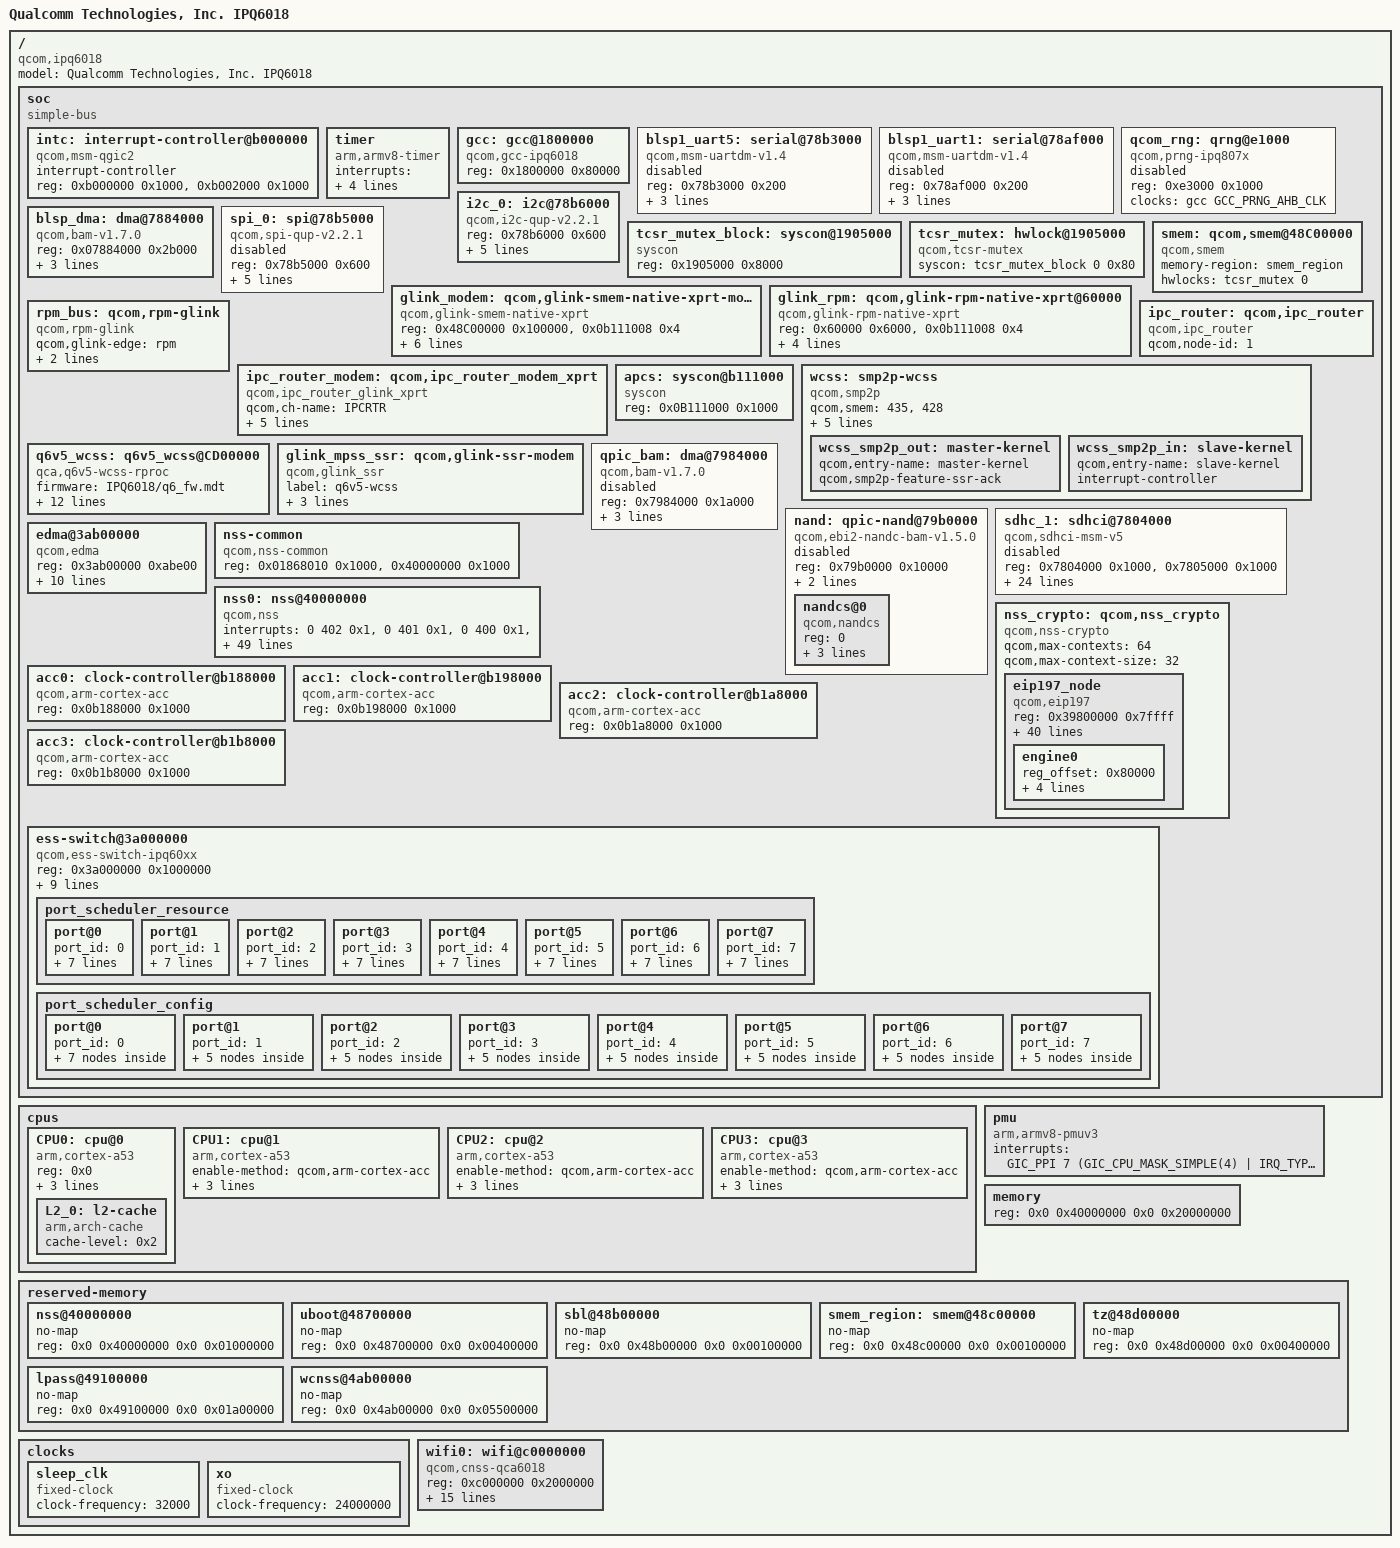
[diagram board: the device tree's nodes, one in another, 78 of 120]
/*
 * Copyright (c) 2018, The Linux Foundation. All rights reserved.
 *
 * Permission to use, copy, modify, and/or distribute this software for any
 * purpose with or without fee is hereby granted, provided that the above
 * copyright notice and this permission notice appear in all copies.
 *
 * THE SOFTWARE IS PROVIDED "AS IS" AND THE AUTHOR DISCLAIMS ALL WARRANTIES
 * WITH REGARD TO THIS SOFTWARE INCLUDING ALL IMPLIED WARRANTIES OF
 * MERCHANTABILITY AND FITNESS. IN NO EVENT SHALL THE AUTHOR BE LIABLE FOR
 * ANY SPECIAL, DIRECT, INDIRECT, OR CONSEQUENTIAL DAMAGES OR ANY DAMAGES
 * WHATSOEVER RESULTING FROM LOSS OF USE, DATA OR PROFITS, WHETHER IN AN
 * ACTION OF CONTRACT, NEGLIGENCE OR OTHER TORTIOUS ACTION, ARISING OUT OF
 * OR IN CONNECTION WITH THE USE OR PERFORMANCE OF THIS SOFTWARE.
 */

#include <dt-bindings/interrupt-controller/arm-gic.h>
#include <dt-bindings/clock/qcom,gcc-ipq6018.h>

/ {
	model = "Qualcomm Technologies, Inc. IPQ6018";
	compatible = "qcom,ipq6018";

	soc: soc {
		#address-cells = <0x1>;
		#size-cells = <0x1>;
		ranges = <0 0 0 0xffffffff>;
		compatible = "simple-bus";

		intc: interrupt-controller@b000000 {
			compatible = "qcom,msm-qgic2";
			interrupt-controller;
			#interrupt-cells = <0x3>;
			reg = <0xb000000 0x1000>, <0xb002000 0x1000>;
		};

		timer {
			compatible = "arm,armv8-timer";
			interrupts = <GIC_PPI 2 (GIC_CPU_MASK_SIMPLE(4) | IRQ_TYPE_LEVEL_LOW)>,
				     <GIC_PPI 3 (GIC_CPU_MASK_SIMPLE(4) | IRQ_TYPE_LEVEL_LOW)>,
				     <GIC_PPI 4 (GIC_CPU_MASK_SIMPLE(4) | IRQ_TYPE_LEVEL_LOW)>,
				     <GIC_PPI 1 (GIC_CPU_MASK_SIMPLE(4) | IRQ_TYPE_LEVEL_LOW)>;
		};

		gcc: gcc@1800000 {
			compatible = "qcom,gcc-ipq6018";
			reg = <0x1800000 0x80000>;
			#clock-cells = <0x1>;
			#reset-cells = <0x1>;
		};

		blsp1_uart5: serial@78b3000 {
			compatible = "qcom,msm-uartdm-v1.4", "qcom,msm-uartdm";
			reg = <0x78b3000 0x200>;
			interrupts = <GIC_SPI 308 IRQ_TYPE_LEVEL_HIGH>;
			clocks = <&gcc GCC_BLSP1_UART5_APPS_CLK>,
				 <&gcc GCC_BLSP1_AHB_CLK>;
			clock-names = "core", "iface";
			status = "disabled";
		};

		blsp1_uart1: serial@78af000 {
			compatible = "qcom,msm-uartdm-v1.4", "qcom,msm-uartdm";
			reg = <0x78af000 0x200>;
			interrupts = <GIC_SPI 107 IRQ_TYPE_LEVEL_HIGH>;
			clocks = <&gcc GCC_BLSP1_UART1_APPS_CLK>,
				 <&gcc GCC_BLSP1_AHB_CLK>;
			clock-names = "core", "iface";
			status = "disabled";
		};

		qcom_rng: qrng@e1000 {
			compatible = "qcom,prng-ipq807x";
			reg = <0xe3000 0x1000>;
			clocks = <&gcc GCC_PRNG_AHB_CLK>;
			clock-names = "core";
			status = "disabled";
		};

		blsp_dma: dma@7884000 {
			compatible = "qcom,bam-v1.7.0";
			reg = <0x07884000 0x2b000>;
			interrupts = <0 238 0>;
			clocks = <&gcc GCC_BLSP1_AHB_CLK>;
			clock-names = "bam_clk";
			#dma-cells = <1>;
			qcom,ee = <0>;
		};

		i2c_0: i2c@78b6000 {
			compatible = "qcom,i2c-qup-v2.2.1";
			#address-cells = <1>;
			#size-cells = <0>;
			reg = <0x78b6000 0x600>;
			interrupts = <GIC_SPI 96 0x4>;
			clocks = <&gcc GCC_BLSP1_AHB_CLK>,
				<&gcc GCC_BLSP1_QUP2_I2C_APPS_CLK>;
			clock-names = "iface", "core";
			clock-frequency  = <400000>;
			dmas = <&blsp_dma 15>, <&blsp_dma 14>;
			dma-names = "rx", "tx";
		};

		spi_0: spi@78b5000 { /* BLSP1 QUP0 */
			compatible = "qcom,spi-qup-v2.2.1";
			#address-cells = <1>;
			#size-cells = <0>;
			reg = <0x78b5000 0x600>;
			interrupts = <0 95 0>;
			spi-max-frequency = <50000000>;
			clocks = <&gcc GCC_BLSP1_QUP1_SPI_APPS_CLK>,
				<&gcc GCC_BLSP1_AHB_CLK>;
			clock-names = "core", "iface";
			dmas = <&blsp_dma 12>, <&blsp_dma 13>;
			dma-names = "tx", "rx";
			status = "disabled";
		};

		tcsr_mutex_block: syscon@1905000 {
			compatible = "syscon";
			reg = <0x1905000 0x8000>;
		};

		tcsr_mutex: hwlock@1905000 {
			compatible = "qcom,tcsr-mutex";
			syscon = <&tcsr_mutex_block 0 0x80>;
			#hwlock-cells = <1>;
		};

		smem: qcom,smem@48C00000 {
			compatible = "qcom,smem";
			memory-region = <&smem_region>;
			hwlocks = <&tcsr_mutex 0>;
		};

		glink_modem: qcom,glink-smem-native-xprt-modem@48C00000 {
			compatible = "qcom,glink-smem-native-xprt";
			reg = <0x48C00000 0x100000>, <0x0b111008 0x4>;
			reg-names = "smem", "irq-reg-base";
			qcom,irq-mask = <0x100>;
			interrupts = <0 321 1>;
			label = "mpss";
			qcom,subsys-id = <1>;
			smem-entry = <478>, <479>, <480>;
			smem-entry-names = "ch", "tx_fifo", "rx_fifo";
		};

		glink_rpm: qcom,glink-rpm-native-xprt@60000 {
			compatible = "qcom,glink-rpm-native-xprt";
			reg = <0x60000 0x6000>, <0x0b111008 0x4>;
			reg-names = "msgram", "irq-reg-base";
			qcom,irq-mask = <0x1>;
			interrupts = <GIC_SPI 168 IRQ_TYPE_EDGE_RISING>;
			label = "rpm";
			qcom,subsys-id = <6>;
			status = "ok";
		};

		rpm_bus: qcom,rpm-glink {
			compatible = "qcom,rpm-glink";
			qcom,glink-edge = "rpm";
			rpm-channel-name = "rpm_requests";
			qcom,rpm-channel-type = <15>; //SMD_APPS_RPM
			status = "ok";
		};

		ipc_router: qcom,ipc_router {
			compatible = "qcom,ipc_router";
			qcom,node-id = <1>;
		};

		ipc_router_modem: qcom,ipc_router_modem_xprt {
			compatible = "qcom,ipc_router_glink_xprt";
			qcom,ch-name = "IPCRTR";
			qcom,xprt-remote = "mpss";
			qcom,glink-xprt = "smem";
			qcom,xprt-linkid = <1>;
			qcom,xprt-version = <1>;
			qcom,fragmented-data;
		};

		apcs: syscon@b111000 {
			compatible = "syscon";
			reg = <0x0B111000 0x1000>;
		};

		wcss: smp2p-wcss {
			compatible = "qcom,smp2p";
			qcom,smem = <435>, <428>;

			interrupt-parent = <&intc>;
			interrupts = <0 322 1>;

			qcom,ipc = <&apcs 8 9>;

			qcom,local-pid = <0>;
			qcom,remote-pid = <1>;

			wcss_smp2p_out: master-kernel {
				qcom,entry-name = "master-kernel";
				qcom,smp2p-feature-ssr-ack;
				#qcom,smem-state-cells = <1>;
			};

			wcss_smp2p_in: slave-kernel {
				qcom,entry-name = "slave-kernel";

				interrupt-controller;
				#interrupt-cells = <2>;
			};
		};

		q6v5_wcss: q6v5_wcss@CD00000 {
			compatible = "qca,q6v5-wcss-rproc";
			firmware = "IPQ6018/q6_fw.mdt";
			reg = <0xCD00000 0x4040>,
				<0x194f000 0x10>,
				<0x1952000 0x10>,
				<0x4ab000 0x20>,
				<0x1818000 0x110>,
				<0x1859000 0x10>,
				<0x1945000 0x10>;
			reg-names = "wcss-base",
					"tcsr-q6-base",
					"tcsr-base",
					"mpm-base",
					"gcc-wcss-bcr-base",
					"gcc-wcss-misc-base",
					"tcsr-global";
			qca,auto-restart;
			qca,extended-intc;
			interrupts-extended = <&intc 0 325 1>,
				<&wcss_smp2p_in 0 0>,
				<&wcss_smp2p_in 1 0>,
				<&wcss_smp2p_in 3 0>;
			interrupt-names = "wdog",
				  "qcom,gpio-err-fatal",
				  "qcom,gpio-err-ready",
				  "qcom,gpio-stop-ack";
			qcom,smem-states = <&wcss_smp2p_out 0>,
				   <&wcss_smp2p_out 1>;
			qcom,smem-state-names = "shutdown",
					"stop";
		};

		glink_mpss_ssr: qcom,glink-ssr-modem {
			compatible = "qcom,glink_ssr";
			label = "q6v5-wcss";
			qcom,edge = "mpss";
			qca,no-notify-edges;
			qcom,xprt = "smem";
		};

		qpic_bam: dma@7984000{
			compatible = "qcom,bam-v1.7.0";
			reg = <0x7984000 0x1a000>;
			interrupts = <0 146 0>;
			clocks = <&gcc GCC_QPIC_AHB_CLK>;
			clock-names = "bam_clk";
			#dma-cells = <1>;
			qcom,ee = <0>;
			status = "disbaled";
		};

		nand: qpic-nand@79b0000 {
			compatible = "qcom,ebi2-nandc-bam-v1.5.0";
			reg = <0x79b0000 0x10000>;
			#address-cells = <1>;
			#size-cells = <0>;
			clocks = <&gcc GCC_QPIC_CLK>,
				<&gcc GCC_QPIC_AHB_CLK>;
			clock-names = "core", "aon";

			dmas = <&qpic_bam 0>,
				<&qpic_bam 1>,
				<&qpic_bam 2>;
			dma-names = "tx", "rx", "cmd";
			status = "disabled";

			nandcs@0 {
				compatible = "qcom,nandcs";
				reg = <0>;
				#address-cells = <1>;
				#size-cells = <1>;

				nand-ecc-strength = <4>;
				nand-ecc-step-size = <512>;
				nand-bus-width = <8>;
			};
		};

		sdhc_1: sdhci@7804000 {
			compatible = "qcom,sdhci-msm-v5";
			reg = <0x7804000 0x1000>, <0x7805000 0x1000>;
			reg-names = "hc_mem", "cmdq_mem";

			interrupts = <0 123 0>, <0 138 0>;
			interrupt-names = "hc_irq", "pwr_irq";

			qcom,bus-width = <8>;

			qcom,dedicated-io = <1>;

			/* device core power supply */
			qcom,vdd-voltage-level = <2900000 2900000>;
			qcom,vdd-current-level = <200 570000>;

			/* device communication power supply */
			qcom,vdd-io-lpm-sup;
			qcom,vdd-io-voltage-level = <1800000 1800000>;
			qcom,vdd-io-current-level = <200 325000>;
			qcom,vdd-io-always-on;

			qcom,cpu-dma-latency-us = <701>;
			qcom,msm-bus,name = "sdhc1";
			qcom,msm-bus,num-cases = <9>;
			qcom,msm-bus,num-paths = <1>;
			qcom,msm-bus,vectors-KBps = <78 512 0 0>, /* No vote */
				<78 512 1046 3200>,    /* 400 KB/s*/
				<78 512 52286 160000>, /* 20 MB/s */
				<78 512 65360 200000>, /* 25 MB/s */
				<78 512 130718 400000>, /* 50 MB/s */
				<78 512 261438 800000>, /* 100 MB/s */
				<78 512 261438 800000>, /* 200 MB/s */
				<78 512 261438 800000>, /* 400 MB/s */
				<78 512 1338562 4096000>; /* Max. bandwidth */
			qcom,bus-bw-vectors-bps = <0 400000 20000000 25000000 \
						50000000 100000000 200000000 \
						400000000 4294967295>;

			clocks = <&gcc GCC_SDCC1_AHB_CLK>,
				 <&gcc GCC_SDCC1_APPS_CLK>;
			clock-names = "iface_clk", "core_clk";
			qcom,large-address-bus;
			qcom,disable-aggressive-pm;

			status = "disabled";
		};

		edma@3ab00000 {
			compatible = "qcom,edma";
			reg = <0x3ab00000 0xabe00>;
			reg-names = "edma-reg-base";
			qcom,txdesc-ring-start = <23>;
			qcom,txdesc-rings = <1>;
			qcom,txcmpl-ring-start = <23>;
			qcom,txcmpl-rings = <1>;
			qcom,rxfill-ring-start = <7>;
			qcom,rxfill-rings = <1>;
			qcom,rxdesc-ring-start = <15>;
			qcom,rxdesc-rings = <1>;
			interrupts = <0 378 4>,
				   <0 354 4>,
				   <0 346 4>,
				   <0 379 4>;
			resets = <&gcc GCC_EDMA_HW_RESET>;
			reset-names = "edma_rst";
		};

		nss-common {
			compatible = "qcom,nss-common";
			reg = <0x01868010 0x1000>, <0x40000000 0x1000>;
			reg-names = "nss-misc-reset", "nss-misc-reset-flag";
		};

		nss0: nss@40000000 {
			compatible = "qcom,nss";
			interrupts = <0 402 0x1>, <0 401 0x1>, <0 400 0x1>,
				     <0 399 0x1>, <0 398 0x1>, <0 397 0x1>,
				     <0 396 0x1>, <0 395 0x1>, <0 394 0x1>;
			reg = <0x39000000 0x1000>, <0x0b111000 0x1000>;
			reg-names = "nphys", "qgic-phys";
			clocks = <&gcc GCC_NSS_NOC_CLK>,
				 <&gcc GCC_NSS_PTP_REF_CLK>,
				 <&gcc GCC_NSS_CSR_CLK>, <&gcc GCC_NSS_CFG_CLK>,
				 <&gcc GCC_NSSNOC_QOSGEN_REF_CLK>,
				 <&gcc GCC_MEM_NOC_NSS_AXI_CLK>,
				 <&gcc GCC_NSSNOC_SNOC_CLK>,
				 <&gcc GCC_NSSNOC_TIMEOUT_REF_CLK>,
				 <&gcc GCC_NSS_CE_AXI_CLK>,
				 <&gcc GCC_NSS_CE_APB_CLK>,
				 <&gcc GCC_NSSNOC_CE_AXI_CLK>,
				 <&gcc GCC_NSSNOC_CE_APB_CLK>,
				 <&gcc GCC_NSSNOC_UBI0_AHB_CLK>,
				 <&gcc GCC_UBI0_CORE_CLK>,
				 <&gcc GCC_UBI0_AHB_CLK>,
				 <&gcc GCC_UBI0_AXI_CLK>,
				 <&gcc GCC_UBI0_NC_AXI_CLK>;
			clock-names = "nss-noc-clk", "nss-ptp-ref-clk",
				      "nss-csr-clk", "nss-cfg-clk",
				      "nss-nssnoc-qosgen-ref-clk",
				      "nss-mem-noc-nss-axi-clk",
				      "nss-nssnoc-snoc-clk",
				      "nss-nssnoc-timeout-ref-clk",
				      "nss-ce-axi-clk", "nss-ce-apb-clk",
				      "nss-nssnoc-ce-axi-clk",
				      "nss-nssnoc-ce-apb-clk",
				      "nss-nssnoc-ahb-clk",
				      "nss-core-clk", "nss-ahb-clk",
				      "nss-axi-clk", "nss-nc-axi-clk";
			qcom,id = <0>;
			qcom,num-queue = <4>;
			qcom,num-irq = <9>;
			qcom,num-pri = <4>;
			qcom,load-addr = <0x40000000>;
			qcom,low-frequency = <748800000>;
			qcom,mid-frequency = <1497600000>;
			qcom,max-frequency = <1497600000>;
			qcom,bridge-enabled;
			qcom,ipv4-enabled;
			qcom,ipv4-reasm-enabled;
			qcom,ipv6-enabled;
			qcom,ipv6-reasm-enabled;
			qcom,wlanredirect-enabled;
			qcom,tun6rd-enabled;
			qcom,l2tpv2-enabled;
			qcom,gre-enabled;
			qcom,gre-redir-enabled;
			qcom,map-t-enabled;
			qcom,portid-enabled;
			qcom,ppe-enabled;
			qcom,pppoe-enabled;
			qcom,pptp-enabled;
			qcom,tunipip6-enabled;
			qcom,shaping-enabled;
			qcom,wlan-dataplane-offload-enabled;
			qcom,vlan-enabled;
			qcom,capwap-enabled;
			qcom,dtls-enabled;
			qcom,crypto-enabled;
			qcom,ipsec-enabled;
		};

		nss_crypto: qcom,nss_crypto {
			compatible = "qcom,nss-crypto";
			qcom,max-contexts = <64>;
			qcom,max-context-size = <32>;
			ranges;

			eip197_node {
				compatible = "qcom,eip197";
				reg-names = "crypto_pbase";
				reg = <0x39800000 0x7ffff>;
				clocks = <&gcc GCC_NSS_CRYPTO_CLK>,
					<&gcc GCC_NSSNOC_CRYPTO_CLK>,
					<&gcc GCC_CRYPTO_PPE_CLK>;
				clock-names = "crypto_clk", "crypto_nocclk",
						"crypto_ppeclk";
				clock-frequency = /bits/ 64 <600000000 600000000 300000000>;
				qcom,dma-mask = <0xff>;
				qcom,transform-enabled;
				qcom,aes128-cbc;
				qcom,aes192-cbc;
				qcom,aes256-cbc;
				qcom,aes128-ctr;
				qcom,aes192-ctr;
				qcom,aes256-ctr;
				qcom,aes128-ecb;
				qcom,aes192-ecb;
				qcom,aes256-ecb;
				qcom,3des-cbc;
				qcom,sha160-hash;
				qcom,sha224-hash;
				qcom,sha256-hash;
				qcom,sha160-hmac;
				qcom,sha256-hmac;
				qcom,sha384-hmac;
				qcom,sha512-hmac;
				qcom,aes128-gcm-gmac;
				qcom,aes192-gcm-gmac;
				qcom,aes256-gcm-gmac;
				qcom,aes128-cbc-sha160-hmac;
				qcom,aes192-cbc-sha160-hmac;
				qcom,aes256-cbc-sha160-hmac;
				qcom,aes128-ctr-sha160-hmac;
				qcom,aes192-ctr-sha160-hmac;
				qcom,aes256-ctr-sha160-hmac;
				qcom,3des-cbc-sha160-hmac;
				qcom,aes128-cbc-sha256-hmac;
				qcom,aes192-cbc-sha256-hmac;
				qcom,aes256-cbc-sha256-hmac;
				qcom,aes128-ctr-sha256-hmac;
				qcom,aes192-ctr-sha256-hmac;
				qcom,aes256-ctr-sha256-hmac;
				qcom,3des-cbc-sha256-hmac;

				engine0 {
					reg_offset = <0x80000>;
					qcom,ifpp-enabled;
					qcom,ipue-enabled;
					qcom,ofpp-enabled;
					qcom,opue-enabled;
				};
			};
		};

		acc0:clock-controller@b188000 {
			compatible = "qcom,arm-cortex-acc";
			reg = <0x0b188000 0x1000>;
		};

		acc1:clock-controller@b198000 {
			compatible = "qcom,arm-cortex-acc";
			reg = <0x0b198000 0x1000>;
		};

		acc2:clock-controller@b1a8000 {
			compatible = "qcom,arm-cortex-acc";
			reg = <0x0b1a8000 0x1000>;
		};

		acc3:clock-controller@b1b8000 {
			compatible = "qcom,arm-cortex-acc";
			reg = <0x0b1b8000 0x1000>;
		};

		ess-switch@3a000000 {
			compatible = "qcom,ess-switch-ipq60xx";
			reg = <0x3a000000 0x1000000>;
			switch_access_mode = "local bus";
			switch_cpu_bmp = <0x1>;  /* cpu port bitmap */
			switch_lan_bmp = <0x1e>; /* lan port bitmap */
			switch_wan_bmp = <0x20>; /* wan port bitmap */
			switch_mac_mode = <0x0>; /* mac mode for uniphy 0*/
			switch_mac_mode1 = <0xd>; /* mac mode for uniphy 1*/
			switch_mac_mode2 = <0xff>; /* mac mode for uniphy 2*/
			bm_tick_mode = <0>; /* bm tick mode */
			tm_tick_mode = <0>; /* tm tick mode */
			port_scheduler_resource {
				port@0 {
					port_id = <0>;
					ucast_queue = <0 143>;
					mcast_queue = <256 271>;
					l0sp = <0 35>;
					l0cdrr = <0 47>;
					l0edrr = <0 47>;
					l1cdrr = <0 7>;
					l1edrr = <0 7>;
				};
				port@1 {
					port_id = <1>;
					ucast_queue = <144 159>;
					mcast_queue = <272 275>;
					l0sp = <36 39>;
					l0cdrr = <48 63>;
					l0edrr = <48 63>;
					l1cdrr = <8 11>;
					l1edrr = <8 11>;
				};
				port@2 {
					port_id = <2>;
					ucast_queue = <160 175>;
					mcast_queue = <276 279>;
					l0sp = <40 43>;
					l0cdrr = <64 79>;
					l0edrr = <64 79>;
					l1cdrr = <12 15>;
					l1edrr = <12 15>;
				};
				port@3 {
					port_id = <3>;
					ucast_queue = <176 191>;
					mcast_queue = <280 283>;
					l0sp = <44 47>;
					l0cdrr = <80 95>;
					l0edrr = <80 95>;
					l1cdrr = <16 19>;
					l1edrr = <16 19>;
				};
				port@4 {
					port_id = <4>;
					ucast_queue = <192 207>;
					mcast_queue = <284 287>;
					l0sp = <48 51>;
					l0cdrr = <96 111>;
					l0edrr = <96 111>;
					l1cdrr = <20 23>;
					l1edrr = <20 23>;
				};
				port@5 {
					port_id = <5>;
					ucast_queue = <208 223>;
					mcast_queue = <288 291>;
					l0sp = <52 55>;
					l0cdrr = <112 127>;
					l0edrr = <112 127>;
					l1cdrr = <24 27>;
					l1edrr = <24 27>;
				};
				port@6 {
					port_id = <6>;
					ucast_queue = <224 239>;
					mcast_queue = <292 295>;
					l0sp = <56 59>;
					l0cdrr = <128 143>;
					l0edrr = <128 143>;
					l1cdrr = <28 31>;
					l1edrr = <28 31>;
				};
				port@7 {
					port_id = <7>;
					ucast_queue = <240 255>;
					mcast_queue = <296 299>;
					l0sp = <60 63>;
					l0cdrr = <144 159>;
					l0edrr = <144 159>;
					l1cdrr = <32 35>;
					l1edrr = <32 35>;
				};
			};
			port_scheduler_config {
				port@0 {
					port_id = <0>;
					l1scheduler {
						group@0 {
							sp = <0 1>; /*L0 SPs*/
							/*cpri cdrr epri edrr*/
							cfg = <0 0 0 0>;
						};
					};
					l0scheduler {
						group@0 {
							/*unicast queues*/
							ucast_queue = <0 4 8>;
							/*multicast queues*/
							mcast_queue = <256 260>;
							/*sp cpricdrrepriedrr*/
							cfg = <0 0 0 0 0>;
						};
						group@1 {
							ucast_queue = <1 5 9>;
							mcast_queue = <257 261>;
							cfg = <0 1 1 1 1>;
						};
						group@2 {
							ucast_queue = <2 6 10>;
							mcast_queue = <258 262>;
							cfg = <0 2 2 2 2>;
						};
						group@3 {
							ucast_queue = <3 7 11>;
							mcast_queue = <259 263>;
							cfg = <0 3 3 3 3>;
						};
					};
				};
				port@1 {
					port_id = <1>;
					l1scheduler {
						group@0 {
							sp = <36>;
							cfg = <0 8 0 8>;
						};
						group@1 {
							sp = <37>;
							cfg = <1 9 1 9>;
						};
					};
					l0scheduler {
						group@0 {
							ucast_queue = <144>;
							ucast_loop_pri = <16>;
							mcast_queue = <272>;
							mcast_loop_pri = <4>;
							cfg = <36 0 48 0 48>;
						};
					};
				};
				port@2 {
					port_id = <2>;
					l1scheduler {
						group@0 {
							sp = <40>;
							cfg = <0 12 0 12>;
						};
						group@1 {
							sp = <41>;
							cfg = <1 13 1 13>;
						};
					};
					l0scheduler {
						group@0 {
							ucast_queue = <160>;
							ucast_loop_pri = <16>;
							mcast_queue = <276>;
							mcast_loop_pri = <4>;
							cfg = <40 0 64 0 64>;
						};
					};
				};
				port@3 {
					port_id = <3>;
					l1scheduler {
						group@0 {
							sp = <44>;
							cfg = <0 16 0 16>;
						};
						group@1 {
							sp = <45>;
							cfg = <1 17 1 17>;
						};
					};
					l0scheduler {
						group@0 {
							ucast_queue = <176>;
							ucast_loop_pri = <16>;
							mcast_queue = <280>;
							mcast_loop_pri = <4>;
							cfg = <44 0 80 0 80>;
						};
					};
				};
				port@4 {
					port_id = <4>;
					l1scheduler {
						group@0 {
							sp = <48>;
							cfg = <0 20 0 20>;
						};
						group@1 {
							sp = <49>;
							cfg = <1 21 1 21>;
						};
					};
					l0scheduler {
						group@0 {
							ucast_queue = <192>;
							ucast_loop_pri = <16>;
							mcast_queue = <284>;
							mcast_loop_pri = <4>;
							cfg = <48 0 96 0 96>;
						};
					};
				};
				port@5 {
					port_id = <5>;
					l1scheduler {
						group@0 {
							sp = <52>;
							cfg = <0 24 0 24>;
						};
						group@1 {
							sp = <53>;
							cfg = <1 25 1 25>;
						};
					};
					l0scheduler {
						group@0 {
							ucast_queue = <208>;
							ucast_loop_pri = <16>;
							mcast_queue = <288>;
							mcast_loop_pri = <4>;
							cfg = <52 0 112 0 112>;
						};
					};
				};
				port@6 {
					port_id = <6>;
					l1scheduler {
						group@0 {
							sp = <56>;
							cfg = <0 28 0 28>;
						};
						group@1 {
							sp = <57>;
							cfg = <1 29 1 29>;
						};
					};
					l0scheduler {
						group@0 {
							ucast_queue = <224>;
							ucast_loop_pri = <16>;
							mcast_queue = <292>;
							mcast_loop_pri = <4>;
							cfg = <56 0 128 0 128>;
						};
					};
				};
				port@7 {
					port_id = <7>;
					l1scheduler {
						group@0 {
							sp = <60>;
							cfg = <0 32 0 32>;
						};
						group@1 {
							sp = <61>;
							cfg = <1 33 1 33>;
						};
					};
					l0scheduler {
						group@0 {
							ucast_queue = <240>;
							ucast_loop_pri = <16>;
							mcast_queue = <296>;
							cfg = <60 0 144 0 144>;
						};
					};
				};
			};
		};

	};

	cpus {
		#address-cells = <0x1>;
		#size-cells = <0x0>;

		CPU0: cpu@0 {
			device_type = "cpu";
			compatible = "arm,cortex-a53";
			reg = <0x0>;
			enable-method = "qcom,arm-cortex-acc";
			qcom,acc = <&acc0>;
			next-level-cache = <&L2_0>;

			L2_0: l2-cache {
				compatible = "arm,arch-cache";
				cache-level = <0x2>;
			};
		};

		CPU1: cpu@1 {
			device_type = "cpu";
			compatible = "arm,cortex-a53";
			enable-method = "qcom,arm-cortex-acc";
			qcom,acc = <&acc1>;
			reg = <0x1>;
			next-level-cache = <&L2_0>;
		};

		CPU2: cpu@2 {
			device_type = "cpu";
			compatible = "arm,cortex-a53";
			enable-method = "qcom,arm-cortex-acc";
			qcom,acc = <&acc2>;
			reg = <0x2>;
			next-level-cache = <&L2_0>;
		};

		CPU3: cpu@3 {
			device_type = "cpu";
			compatible = "arm,cortex-a53";
			enable-method = "qcom,arm-cortex-acc";
			qcom,acc = <&acc3>;
			reg = <0x3>;
			next-level-cache = <&L2_0>;
		};
	};

	pmu {
		compatible = "arm,armv8-pmuv3";
		interrupts = <GIC_PPI 7 (GIC_CPU_MASK_SIMPLE(4) |
					 IRQ_TYPE_LEVEL_HIGH)>;
	};

	memory {
		device_type = "memory";
		reg = <0x0 0x40000000 0x0 0x20000000>;
	};

	/*
	 * +=========+==============+========================+
	 * |        |              |                         |
	 * | Region | Start Offset |          Size           |
	 * |        |              |                         |
	 * +--------+--------------+-------------------------+
	 * |        |              |                         |
	 * |        |              |                         |
	 * |  NSS   |  0x40000000  |          16MB           |
	 * |        |              |                         |
	 * |        |              |                         |
	 * +--------+--------------+-------------------------+
	 * |        |              |                         |
	 * |        |              |                         |
	 * |        |              |                         |
	 * |        |              |                         |
	 * | Linux  |  0x41000000  |         119MB           |
	 * |        |              |                         |
	 * |        |              |                         |
	 * |        |              |                         |
	 * +--------+--------------+-------------------------+
	 * |        |              |                         |
	 * | uboot  |  0x48700000  |           4MB           |
	 * |        |              |                         |
	 * +--------+--------------+-------------------------+
	 * |  SBL   |  0x48B00000  |           1MB           |
	 * +--------+--------------+-------------------------+
	 * |  smem  |  0x48C00000  |           1MB           |
	 * +--------+--------------+-------------------------+
	 * |        |              |                         |
	 * | TZ+HYP |  0x48D00000  |           4MB           |
	 * |        |              |                         |
	 * +--------+--------------+-------------------------+
	 * |        |              |                         |
	 * |        |              |                         |
	 * | LPASS  |              |                         |
	 * |   Q6   |  0x49100000  |          26MB           |
	 * |        |              |                         |
	 * |        |              |                         |
	 * |        |              |                         |
	 * +--------+--------------+-------------------------+
	 * |        |              |                         |
	 * |        |              |                         |
	 * | WLAN   |              |                         |
	 * |   Q6   |  0x4AB00000  |          85MB           |
	 * |        |              |                         |
	 * |        |              |                         |
	 * |        |              |                         |
	 * +--------+--------------+-------------------------+
	 * |                                                 |
	 * |            256MB memory for Linux               |
	 * |                                                 |
	 * +=================================================+
	 */

	reserved-memory {
		#address-cells = <2>;
		#size-cells = <2>;
		ranges;

		nss@40000000 {
			no-map;
			reg = <0x0 0x40000000 0x0 0x01000000>;
		};

		uboot@48700000 {
			no-map;
			reg = <0x0 0x48700000 0x0 0x00400000>;
		};

		sbl@48b00000 {
			no-map;
			reg = <0x0 0x48b00000 0x0 0x00100000>;
		};

		smem_region:smem@48c00000 {
			no-map;
			reg = <0x0 0x48c00000 0x0 0x00100000>;
		};

		tz@48d00000 {
			no-map;
			reg = <0x0 0x48d00000 0x0 0x00400000>;
		};

		lpass@49100000 {
			no-map;
			reg = <0x0 0x49100000 0x0 0x01a00000>;
		};

		wcnss@4ab00000 {
			no-map;
			reg = <0x0 0x4ab00000 0x0 0x05500000>;
		};

	};

	clocks {
		sleep_clk: sleep_clk {
			compatible = "fixed-clock";
			clock-frequency = <32000>;
			#clock-cells = <0>;
		};

		xo: xo {
			compatible = "fixed-clock";
			clock-frequency = <24000000>;
			#clock-cells = <0>;
		};
	};

	wifi0: wifi@c0000000 {
		compatible = "qcom,cnss-qca6018";
		reg = <0xc000000 0x2000000>;
		qcom,hw-mode-id = <1>;
		qcom,tgt-mem-mode = <0>;
		qcom,bdf-addr = <0x4BE00000 0x4BE00000>;
		qcom,caldb-addr = <0x4BE40000 0x4BE40000>;
		interrupts = <0 320 1>, /* o_wcss_apps_intr[0] =  */
			<0 319 1>,
			<0 318 1>,
			<0 317 1>,
			<0 316 1>,
			<0 315 1>,
			<0 314 1>,
			<0 311 1>,
			<0 310 1>,
			<0 411 1>,
			<0 410 1>,
			<0 40 1>,
			<0 39 1>,
			<0 302 1>,
			<0 301 1>,
			<0 37 1>,
			<0 36 1>,
			<0 296 1>,
			<0 295 1>,
			<0 294 1>,
			<0 293 1>,
			<0 292 1>,
			<0 291 1>,
			<0 290 1>,
			<0 289 1>,
			<0 288 1>, /* o_wcss_apps_intr[25] */

			<0 239 1>,
			<0 236 1>,
			<0 235 1>,
			<0 234 1>,
			<0 233 1>,
			<0 232 1>,
			<0 231 1>,
			<0 230 1>,
			<0 229 1>,
			<0 228 1>,
			<0 224 1>,
			<0 223 1>,

			<0 203 1>,

			<0 183 1>,
			<0 180 1>,
			<0 179 1>,
			<0 178 1>,
			<0 177 1>,
			<0 176 1>,

			<0 163 1>,
			<0 162 1>,
			<0 160 1>,
			<0 159 1>,
			<0 158 1>,
			<0 157 1>,
			<0 156 1>; /* o_wcss_apps_intr[51] */

		interrupt-names = "misc-pulse1",
			"misc-latch",
			"sw-exception",
			"watchdog",
			"ce0",
			"ce1",
			"ce2",
			"ce3",
			"ce4",
			"ce5",
			"ce6",
			"ce7",
			"ce8",
			"ce9",
			"ce10",
			"ce11",
			"host2wbm-desc-feed",
			"host2reo-re-injection",
			"host2reo-command",
			"host2rxdma-monitor-ring3",
			"host2rxdma-monitor-ring2",
			"host2rxdma-monitor-ring1",
			"reo2ost-exception",
			"wbm2host-rx-release",
			"reo2host-status",
			"reo2host-destination-ring4",
			"reo2host-destination-ring3",
			"reo2host-destination-ring2",
			"reo2host-destination-ring1",
			"rxdma2host-monitor-destination-mac3",
			"rxdma2host-monitor-destination-mac2",
			"rxdma2host-monitor-destination-mac1",
			"ppdu-end-interrupts-mac3",
			"ppdu-end-interrupts-mac2",
			"ppdu-end-interrupts-mac1",
			"rxdma2host-monitor-status-ring-mac3",
			"rxdma2host-monitor-status-ring-mac2",
			"rxdma2host-monitor-status-ring-mac1",
			"host2rxdma-host-buf-ring-mac3",
			"host2rxdma-host-buf-ring-mac2",
			"host2rxdma-host-buf-ring-mac1",
			"rxdma2host-destination-ring-mac3",
			"rxdma2host-destination-ring-mac2",
			"rxdma2host-destination-ring-mac1",
			"host2tcl-input-ring4",
			"host2tcl-input-ring3",
			"host2tcl-input-ring2",
			"host2tcl-input-ring1",
			"wbm2host-tx-completions-ring3",
			"wbm2host-tx-completions-ring2",
			"wbm2host-tx-completions-ring1",
			"tcl2host-status-ring";
		status = "ok";
	};
};
